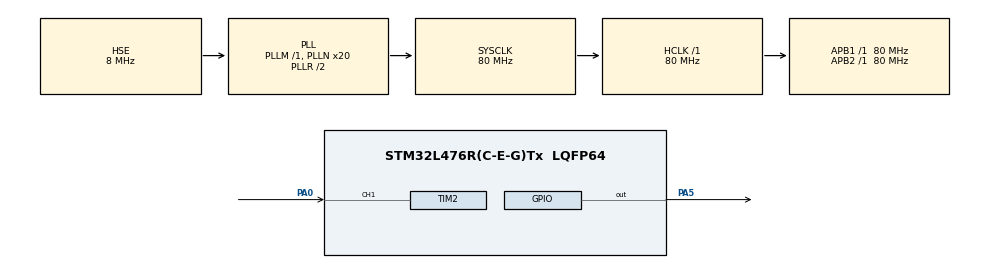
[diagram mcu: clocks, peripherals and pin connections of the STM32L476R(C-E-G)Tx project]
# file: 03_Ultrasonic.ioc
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Mcu.Family=STM32L4
Mcu.Name=STM32L476R(C-E-G)Tx
Mcu.Package=LQFP64
NVIC.PriorityGroup=NVIC_PRIORITYGROUP_4
NVIC.TIM2_IRQn=true\:0\:0\:false\:false\:true\:true\:true\:true
PA0.Signal=S_TIM2_CH1
PA5.Signal=GPIO_Output
PH0-OSC_IN\ (PH0).Mode=HSE-External-Oscillator
PH0-OSC_IN\ (PH0).Signal=RCC_OSC_IN
PH1-OSC_OUT\ (PH1).Mode=HSE-External-Oscillator
PH1-OSC_OUT\ (PH1).Signal=RCC_OSC_OUT
ProjectManager.HeapSize=0x200
ProjectManager.StackSize=0x400
ProjectManager.TargetToolchain=STM32CubeIDE
RCC.ADCFreq_Value=32000000
RCC.AHBFreq_Value=80000000
RCC.APB1Freq_Value=80000000
RCC.APB1TimFreq_Value=80000000
RCC.APB2Freq_Value=80000000
RCC.APB2TimFreq_Value=80000000
RCC.CortexFreq_Value=80000000
RCC.HCLKFreq_Value=80000000
RCC.HSE_VALUE=8000000
RCC.HSI_VALUE=16000000
RCC.LSE_VALUE=32768
RCC.MSI_VALUE=4000000
RCC.PLLN=20
RCC.PLLSourceVirtual=RCC_PLLSOURCE_HSE
RCC.SYSCLKFreq_VALUE=80000000
RCC.SYSCLKSource=RCC_SYSCLKSOURCE_PLLCLK
RCC.USBFreq_Value=32000000
RCC.VCOOutputFreq_Value=160000000
SH.S_TIM2_CH1.0=TIM2_CH1,Input_Capture1_from_TI1
TIM2.Channel-Input_Capture1_from_TI1=TIM_CHANNEL_1
TIM2.Prescaler=80-1
board=custom

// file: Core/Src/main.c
/* USER CODE BEGIN Header */
/**
  ******************************************************************************
  * @file           : main.c
  * @brief          : Main program body
  ******************************************************************************
  * @attention
  *
  * Copyright (c) 2026 STMicroelectronics.
  * All rights reserved.
  *
  * This software is licensed under terms that can be found in the LICENSE file
  * in the root directory of this software component.
  * If no LICENSE file comes with this software, it is provided AS-IS.
  *
  ******************************************************************************
  */
/* USER CODE END Header */
#include "main.h"

/* USER CODE BEGIN Includes */
#include <stdio.h>
/* USER CODE END Includes */

TIM_HandleTypeDef htim2;

/* USER CODE BEGIN PV */
uint32_t IC_Val1 = 0;
uint32_t IC_Val2 = 0;

uint8_t Is_First_Captured = 0;

uint32_t Difference = 0;
float Distance = 0;
/* USER CODE END PV */

void SystemClock_Config(void);
static void MX_GPIO_Init(void);
static void MX_TIM2_Init(void);

/* USER CODE BEGIN 0 */
void delay_us(uint16_t time)
{
	__HAL_TIM_SET_COUNTER(&htim2,0);
	while(__HAL_TIM_GET_COUNTER(&htim2) < time);

}

void HCSR04_Trigger(void)
{
    HAL_GPIO_WritePin(GPIOA, GPIO_PIN_5, GPIO_PIN_RESET);
    delay_us(2);

    HAL_GPIO_WritePin(GPIOA, GPIO_PIN_5, GPIO_PIN_SET);
    delay_us(10);

    HAL_GPIO_WritePin(GPIOA, GPIO_PIN_5, GPIO_PIN_RESET);
}

void HAL_TIM_IC_CaptureCallback(TIM_HandleTypeDef *htim)
{
    if(htim->Channel == HAL_TIM_ACTIVE_CHANNEL_1)
    {
        if(Is_First_Captured == 0)
        {
            IC_Val1 = HAL_TIM_ReadCapturedValue(htim,
                                                TIM_CHANNEL_1);

            Is_First_Captured = 1;

            __HAL_TIM_SET_CAPTUREPOLARITY(htim,
                                          TIM_CHANNEL_1,
                                          TIM_INPUTCHANNELPOLARITY_FALLING);
        }
        else
        {
            IC_Val2 = HAL_TIM_ReadCapturedValue(htim,
                                                TIM_CHANNEL_1);

            __HAL_TIM_SET_COUNTER(htim,0);

            if(IC_Val2 > IC_Val1)
                Difference = IC_Val2 - IC_Val1;
            else
                Difference = (65535 - IC_Val1) + IC_Val2;

            Distance = Difference * 0.0343f / 2.0f;

            Is_First_Captured = 0;

            __HAL_TIM_SET_CAPTUREPOLARITY(htim,
                                          TIM_CHANNEL_1,
                                          TIM_INPUTCHANNELPOLARITY_RISING);
        }
    }
}

/* USER CODE END 0 */

int main(void)
{

  /* MCU Configuration--------------------------------------------------------*/

  /* Reset of all peripherals, Initializes the Flash interface and the Systick. */
  HAL_Init();

  /* Configure the system clock */
  SystemClock_Config();

  /* Initialize all configured peripherals */
  MX_GPIO_Init();
  MX_TIM2_Init();
  /* USER CODE BEGIN 2 */
  HAL_TIM_IC_Start_IT(&htim2, TIM_CHANNEL_1);
  /* USER CODE END 2 */

  /* Infinite loop */
  while (1)
  {
	    HCSR04_Trigger();

	    HAL_Delay(100);

	    printf("Distance = %.2f cm\r\n", Distance);
  }
}

void SystemClock_Config(void)
{
  RCC_OscInitTypeDef RCC_OscInitStruct = {0};
  RCC_ClkInitTypeDef RCC_ClkInitStruct = {0};

  /** Configure the main internal regulator output voltage
  */
  if (HAL_PWREx_ControlVoltageScaling(PWR_REGULATOR_VOLTAGE_SCALE1) != HAL_OK)
  {
    Error_Handler();
  }

  /** Initializes the RCC Oscillators according to the specified parameters
  * in the RCC_OscInitTypeDef structure.
  */
  RCC_OscInitStruct.OscillatorType = RCC_OSCILLATORTYPE_HSE;
  RCC_OscInitStruct.HSEState = RCC_HSE_ON;
  RCC_OscInitStruct.PLL.PLLState = RCC_PLL_ON;
  RCC_OscInitStruct.PLL.PLLSource = RCC_PLLSOURCE_HSE;
  RCC_OscInitStruct.PLL.PLLM = 1;
  RCC_OscInitStruct.PLL.PLLN = 20;
  RCC_OscInitStruct.PLL.PLLP = RCC_PLLP_DIV7;
  RCC_OscInitStruct.PLL.PLLQ = RCC_PLLQ_DIV2;
  RCC_OscInitStruct.PLL.PLLR = RCC_PLLR_DIV2;
  if (HAL_RCC_OscConfig(&RCC_OscInitStruct) != HAL_OK)
  {
    Error_Handler();
  }

  /** Initializes the CPU, AHB and APB buses clocks
  */
  RCC_ClkInitStruct.ClockType = RCC_CLOCKTYPE_HCLK|RCC_CLOCKTYPE_SYSCLK
                              |RCC_CLOCKTYPE_PCLK1|RCC_CLOCKTYPE_PCLK2;
  RCC_ClkInitStruct.SYSCLKSource = RCC_SYSCLKSOURCE_PLLCLK;
  RCC_ClkInitStruct.AHBCLKDivider = RCC_SYSCLK_DIV1;
  RCC_ClkInitStruct.APB1CLKDivider = RCC_HCLK_DIV1;
  RCC_ClkInitStruct.APB2CLKDivider = RCC_HCLK_DIV1;

  if (HAL_RCC_ClockConfig(&RCC_ClkInitStruct, FLASH_LATENCY_4) != HAL_OK)
  {
    Error_Handler();
  }
}

static void MX_TIM2_Init(void)
{

  TIM_MasterConfigTypeDef sMasterConfig = {0};
  TIM_IC_InitTypeDef sConfigIC = {0};

  htim2.Instance = TIM2;
  htim2.Init.Prescaler = 80-1;
  htim2.Init.CounterMode = TIM_COUNTERMODE_UP;
  htim2.Init.Period = 4294967295;
  htim2.Init.ClockDivision = TIM_CLOCKDIVISION_DIV1;
  htim2.Init.AutoReloadPreload = TIM_AUTORELOAD_PRELOAD_DISABLE;
  if (HAL_TIM_IC_Init(&htim2) != HAL_OK)
  {
    Error_Handler();
  }
  sMasterConfig.MasterOutputTrigger = TIM_TRGO_RESET;
  sMasterConfig.MasterSlaveMode = TIM_MASTERSLAVEMODE_DISABLE;
  if (HAL_TIMEx_MasterConfigSynchronization(&htim2, &sMasterConfig) != HAL_OK)
  {
    Error_Handler();
  }
  sConfigIC.ICPolarity = TIM_INPUTCHANNELPOLARITY_RISING;
  sConfigIC.ICSelection = TIM_ICSELECTION_DIRECTTI;
  sConfigIC.ICPrescaler = TIM_ICPSC_DIV1;
  sConfigIC.ICFilter = 0;
  if (HAL_TIM_IC_ConfigChannel(&htim2, &sConfigIC, TIM_CHANNEL_1) != HAL_OK)
  {
    Error_Handler();
  }

}

static void MX_GPIO_Init(void)
{
  GPIO_InitTypeDef GPIO_InitStruct = {0};

  /* GPIO Ports Clock Enable */
  __HAL_RCC_GPIOH_CLK_ENABLE();
  __HAL_RCC_GPIOA_CLK_ENABLE();

  /*Configure GPIO pin Output Level */
  HAL_GPIO_WritePin(GPIOA, GPIO_PIN_5, GPIO_PIN_RESET);

  /*Configure GPIO pin : PA5 */
  GPIO_InitStruct.Pin = GPIO_PIN_5;
  GPIO_InitStruct.Mode = GPIO_MODE_OUTPUT_PP;
  GPIO_InitStruct.Pull = GPIO_NOPULL;
  GPIO_InitStruct.Speed = GPIO_SPEED_FREQ_LOW;
  HAL_GPIO_Init(GPIOA, &GPIO_InitStruct);

}

void Error_Handler(void)
{
  __disable_irq();
  while (1)
  {
  }
}
